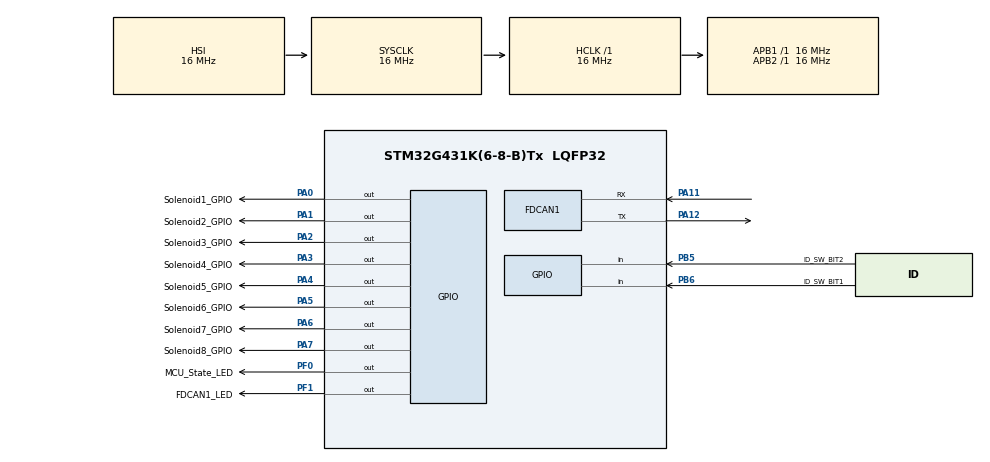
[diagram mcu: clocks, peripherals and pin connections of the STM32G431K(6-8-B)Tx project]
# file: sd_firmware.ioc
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FDCAN1.CalculateBaudRateNominal=333333
FDCAN1.CalculateTimeBitNominal=3000
FDCAN1.CalculateTimeQuantumNominal=1000.0
Mcu.Family=STM32G4
Mcu.Name=STM32G431K(6-8-B)Tx
Mcu.Package=LQFP32
NVIC.PriorityGroup=NVIC_PRIORITYGROUP_4
NVIC.TIM1_UP_TIM16_IRQn=true\:0\:0\:false\:false\:true\:true\:true\:true
PA0.GPIO_Label=Solenoid1_GPIO
PA0.Signal=GPIO_Output
PA1.GPIO_Label=Solenoid2_GPIO
PA1.Signal=GPIO_Output
PA11.Mode=FDCAN_Activate
PA11.Signal=FDCAN1_RX
PA12.Mode=FDCAN_Activate
PA12.Signal=FDCAN1_TX
PA13.Mode=Trace_Asynchronous_SW
PA13.Signal=SYS_JTMS-SWDIO
PA14.Mode=Trace_Asynchronous_SW
PA14.Signal=SYS_JTCK-SWCLK
PA2.GPIO_Label=Solenoid3_GPIO
PA2.Signal=GPIO_Output
PA3.GPIO_Label=Solenoid4_GPIO
PA3.Signal=GPIO_Output
PA4.GPIO_Label=Solenoid5_GPIO
PA4.Signal=GPIO_Output
PA5.GPIO_Label=Solenoid6_GPIO
PA5.Signal=GPIO_Output
PA6.GPIO_Label=Solenoid7_GPIO
PA6.Signal=GPIO_Output
PA7.GPIO_Label=Solenoid8_GPIO
PA7.Signal=GPIO_Output
PB3.Mode=Trace_Asynchronous_SW
PB3.Signal=SYS_JTDO-SWO
PB5.GPIO_Label=ID_SW_BIT2
PB5.Signal=GPIO_Input
PB6.GPIO_Label=ID_SW_BIT1
PB6.Signal=GPIO_Input
PF0-OSC_IN.GPIO_Label=MCU_State_LED
PF0-OSC_IN.Signal=GPIO_Output
PF1-OSC_OUT.GPIO_Label=FDCAN1_LED
PF1-OSC_OUT.Signal=GPIO_Output
ProjectManager.HeapSize=0x200
ProjectManager.StackSize=0x400
ProjectManager.TargetToolchain=CMake
RCC.AHBFreq_Value=16000000
RCC.APB1Freq_Value=16000000
RCC.APB1TimFreq_Value=16000000
RCC.APB2Freq_Value=16000000
RCC.APB2TimFreq_Value=16000000
RCC.CortexFreq_Value=16000000
RCC.EXTERNAL_CLOCK_VALUE=12288000
RCC.HCLKFreq_Value=16000000
RCC.HSE_VALUE=8000000
RCC.HSI48_VALUE=48000000
RCC.HSI_VALUE=16000000
RCC.LSE_VALUE=32768
RCC.SYSCLKFreq_VALUE=16000000
RCC.USBFreq_Value=64000000
RCC.VCOOutputFreq_Value=128000000
TIM16.Prescaler=15
VP_SYS_VS_DBSignals.Mode=DisableDeadBatterySignals
VP_TIM16_VS_ClockSourceINT.Mode=Enable_Timer
board=custom

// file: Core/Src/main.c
/* USER CODE BEGIN Header */
/**
  ******************************************************************************
  * @file           : main.c
  * @brief          : Main program body
  ******************************************************************************
  * @attention
  *
  * Copyright (c) 2026 STMicroelectronics.
  * All rights reserved.
  *
  * This software is licensed under terms that can be found in the LICENSE file
  * in the root directory of this software component.
  * If no LICENSE file comes with this software, it is provided AS-IS.
  *
  ******************************************************************************
  */
/* USER CODE END Header */
#include "main.h"
#include "fdcan.h"
#include "tim.h"
#include "gpio.h"

void SystemClock_Config(void);

int main(void)
{

  /* MCU Configuration--------------------------------------------------------*/

  /* Reset of all peripherals, Initializes the Flash interface and the Systick. */
  HAL_Init();

  /* Configure the system clock */
  SystemClock_Config();

  /* Initialize all configured peripherals */
  MX_GPIO_Init();
  MX_FDCAN1_Init();
  MX_TIM16_Init();
  /* USER CODE BEGIN 2 */
  // FDCANのフィルタ設定と200ms待機後のNodeID取得・通信開始を実行
  FD_CAN1ConfigAndStart();
  HAL_TIM_Base_Start_IT(&htim16); // タイマー割り込み開始
  /* USER CODE END 2 */

  /* Infinite loop */
  while (1)
  {

  }
}

void SystemClock_Config(void)
{
  RCC_OscInitTypeDef RCC_OscInitStruct = {0};
  RCC_ClkInitTypeDef RCC_ClkInitStruct = {0};

  /** Configure the main internal regulator output voltage
  */
  HAL_PWREx_ControlVoltageScaling(PWR_REGULATOR_VOLTAGE_SCALE1);

  /** Initializes the RCC Oscillators according to the specified parameters
  * in the RCC_OscInitTypeDef structure.
  */
  RCC_OscInitStruct.OscillatorType = RCC_OSCILLATORTYPE_HSI;
  RCC_OscInitStruct.HSIState = RCC_HSI_ON;
  RCC_OscInitStruct.HSICalibrationValue = RCC_HSICALIBRATION_DEFAULT;
  RCC_OscInitStruct.PLL.PLLState = RCC_PLL_NONE;
  if (HAL_RCC_OscConfig(&RCC_OscInitStruct) != HAL_OK)
  {
    Error_Handler();
  }

  /** Initializes the CPU, AHB and APB buses clocks
  */
  RCC_ClkInitStruct.ClockType = RCC_CLOCKTYPE_HCLK|RCC_CLOCKTYPE_SYSCLK
                              |RCC_CLOCKTYPE_PCLK1|RCC_CLOCKTYPE_PCLK2;
  RCC_ClkInitStruct.SYSCLKSource = RCC_SYSCLKSOURCE_HSI;
  RCC_ClkInitStruct.AHBCLKDivider = RCC_SYSCLK_DIV1;
  RCC_ClkInitStruct.APB1CLKDivider = RCC_HCLK_DIV1;
  RCC_ClkInitStruct.APB2CLKDivider = RCC_HCLK_DIV1;

  if (HAL_RCC_ClockConfig(&RCC_ClkInitStruct, FLASH_LATENCY_0) != HAL_OK)
  {
    Error_Handler();
  }
}

/* USER CODE BEGIN 4 */
//タイマーの周期ごとに自動で呼ばれる割り込み関数
void HAL_TIM_PeriodElapsedCallback(TIM_HandleTypeDef *htim){
  if (htim->Instance == TIM16){
  //最新のバッファ状態をGPIOへ一括反映
  updateSolenoidOurputs()
  }
}

/* USER CODE END 4 */

void Error_Handler(void)
{
  __disable_irq();
  while (1)
  {
  }
}
